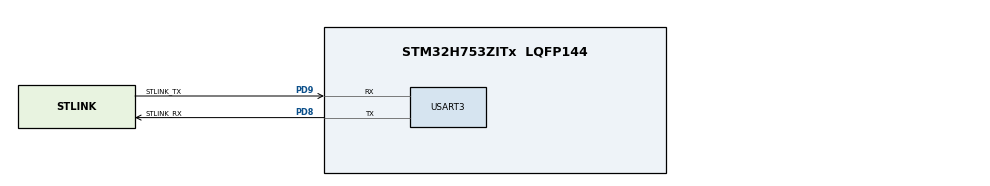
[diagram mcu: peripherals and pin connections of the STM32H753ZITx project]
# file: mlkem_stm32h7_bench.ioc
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CORTEX_M7.CPU_DCache=Disabled
CORTEX_M7.CPU_ICache=Disabled
CORTEX_M7.MPU_Control=MPU_PRIVILEGED_DEFAULT
CORTEX_M7.default_mode_Activation=1
Mcu.Family=STM32H7
Mcu.Name=STM32H753ZITx
Mcu.Package=LQFP144
NVIC.PriorityGroup=NVIC_PRIORITYGROUP_4
NVIC.TIM6_DAC_IRQn=true\:15\:0\:false\:false\:true\:false\:true\:true
NVIC.TimeBase=TIM6_DAC_IRQn
NVIC.TimeBaseIP=TIM6
PC14-OSC32_IN\ (OSC32_IN).Signal=RCC_OSC32_IN
PC15-OSC32_OUT\ (OSC32_OUT).Signal=RCC_OSC32_OUT
PD8.GPIO_Label=STLINK_RX
PD8.Mode=Asynchronous
PD8.Signal=USART3_TX
PD9.GPIO_Label=STLINK_TX
PD9.Mode=Asynchronous
PD9.Signal=USART3_RX
PH0-OSC_IN\ (PH0).Mode=HSE-External-Oscillator
PH0-OSC_IN\ (PH0).Signal=RCC_OSC_IN
PH1-OSC_OUT\ (PH1).Mode=HSE-External-Oscillator
PH1-OSC_OUT\ (PH1).Signal=RCC_OSC_OUT
ProjectManager.HeapSize=0x200
ProjectManager.StackSize=0x400
ProjectManager.TargetToolchain=STM32CubeIDE
RCC.ADCFreq_Value=16125000
RCC.APB1Freq_Value=60000000
RCC.APB2Freq_Value=60000000
RCC.APB3Freq_Value=60000000
RCC.APB4Freq_Value=60000000
RCC.CortexFreq_Value=480000000
RCC.D1PPRE=RCC_APB3_DIV2
RCC.D2PPRE1=RCC_APB1_DIV2
RCC.D2PPRE2=RCC_APB2_DIV2
RCC.D3PPRE=RCC_APB4_DIV2
RCC.DIVM1=4
RCC.DIVN1=480
RCC.DIVQ1=4
RCC.EnbaleCSS=true
RCC.HCLKFreq_Value=120000000
RCC.HPRE=RCC_HCLK_DIV4
RCC.HSE_VALUE=8000000
RCC.PLL2FRACN=0
RCC.PLL3FRACN=0
RCC.PLLFRACN=0
RCC.PLLSourceVirtual=RCC_PLLSOURCE_HSE
RCC.PWR_Regulator_Voltage_Scale=PWR_REGULATOR_VOLTAGE_SCALE2
RCC.SYSCLKFreq_VALUE=480000000
RCC.SYSCLKSource=RCC_SYSCLKSOURCE_PLLCLK
RCC.USBFreq_Value=240000000
TIM2.AutoReloadPreload=TIM_AUTORELOAD_PRELOAD_ENABLE
TIM2.Prescaler=119
USART3.VirtualMode-Asynchronous=VM_ASYNC
VP_MEMORYMAP_VS_MEMORYMAP.Mode=CurAppReg
VP_SYS_VS_tim6.Mode=TIM6
VP_TIM2_VS_ClockSourceINT.Mode=Internal
board=NUCLEO-H753ZI

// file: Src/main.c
/* USER CODE BEGIN Header */
/**
  ******************************************************************************
  * @file           : main.c
  * @brief          : Main program body
  ******************************************************************************
  * @attention
  *
  * Copyright (c) 2026 STMicroelectronics.
  * All rights reserved.
  *
  * This software is licensed under terms that can be found in the LICENSE file
  * in the root directory of this software component.
  * If no LICENSE file comes with this software, it is provided AS-IS.
  *
  ******************************************************************************
  */
/* USER CODE END Header */
#include "main.h"

/* USER CODE BEGIN Includes */
#include "benchmark.h"
/* USER CODE END Includes */

TIM_HandleTypeDef htim2;

UART_HandleTypeDef huart3;

void SystemClock_Config(void);
static void MPU_Config(void);
static void MX_GPIO_Init(void);
static void MX_TIM2_Init(void);
static void MX_USART3_UART_Init(void);

int main(void)
{

  /* MPU Configuration--------------------------------------------------------*/
  MPU_Config();

  /* MCU Configuration--------------------------------------------------------*/

  /* Reset of all peripherals, Initializes the Flash interface and the Systick. */
  HAL_Init();

  /* Configure the system clock */
  SystemClock_Config();

  /* Initialize all configured peripherals */
  MX_GPIO_Init();
  MX_TIM2_Init();
  MX_USART3_UART_Init();
  /* USER CODE BEGIN 2 */
  BenchmarkResult res;
  benchmark_run(&res);
  benchmark_print_results(&res);
  /* USER CODE END 2 */

  /* Infinite loop */
  while (1)
  {

  }
}

void SystemClock_Config(void)
{
  /* MCU boots on HSI 64 MHz by default in Renode.
   * Update CMSIS global for HAL tick calculations. */
  SystemCoreClock = 64000000UL;
}

static void MX_TIM2_Init(void)
{

  TIM_ClockConfigTypeDef sClockSourceConfig = {0};
  TIM_MasterConfigTypeDef sMasterConfig = {0};

  htim2.Instance = TIM2;
  htim2.Init.Prescaler = 63;  /* HSI 64MHz / 64 = 1MHz = 1us/tick (Renode: HSI used) */
  htim2.Init.CounterMode = TIM_COUNTERMODE_UP;
  htim2.Init.Period = 4294967295;
  htim2.Init.ClockDivision = TIM_CLOCKDIVISION_DIV1;
  htim2.Init.AutoReloadPreload = TIM_AUTORELOAD_PRELOAD_ENABLE;
  if (HAL_TIM_Base_Init(&htim2) != HAL_OK)
  {
    Error_Handler();
  }
  sClockSourceConfig.ClockSource = TIM_CLOCKSOURCE_INTERNAL;
  if (HAL_TIM_ConfigClockSource(&htim2, &sClockSourceConfig) != HAL_OK)
  {
    Error_Handler();
  }
  sMasterConfig.MasterOutputTrigger = TIM_TRGO_RESET;
  sMasterConfig.MasterSlaveMode = TIM_MASTERSLAVEMODE_DISABLE;
  if (HAL_TIMEx_MasterConfigSynchronization(&htim2, &sMasterConfig) != HAL_OK)
  {
    Error_Handler();
  }

}

static void MX_USART3_UART_Init(void)
{

  huart3.Instance = USART3;
  huart3.Init.BaudRate = 115200;
  huart3.Init.WordLength = UART_WORDLENGTH_8B;
  huart3.Init.StopBits = UART_STOPBITS_1;
  huart3.Init.Parity = UART_PARITY_NONE;
  huart3.Init.Mode = UART_MODE_TX_RX;
  huart3.Init.HwFlowCtl = UART_HWCONTROL_NONE;
  huart3.Init.OverSampling = UART_OVERSAMPLING_16;
  huart3.Init.OneBitSampling = UART_ONE_BIT_SAMPLE_DISABLE;
  huart3.Init.ClockPrescaler = UART_PRESCALER_DIV1;
  huart3.AdvancedInit.AdvFeatureInit = UART_ADVFEATURE_NO_INIT;
  if (HAL_UART_Init(&huart3) != HAL_OK)
  {
    Error_Handler();
  }
  /* Disable FIFO calls for Renode UART model compatibility */
  /* if (HAL_UARTEx_SetTxFifoThreshold(&huart3, UART_TXFIFO_THRESHOLD_1_8) != HAL_OK)
  {
    Error_Handler();
  }
  if (HAL_UARTEx_SetRxFifoThreshold(&huart3, UART_RXFIFO_THRESHOLD_1_8) != HAL_OK)
  {
    Error_Handler();
  }
  if (HAL_UARTEx_DisableFifoMode(&huart3) != HAL_OK)
  {
    Error_Handler();
  } */

}

static void MX_GPIO_Init(void)
{

  /* GPIO Ports Clock Enable */
  __HAL_RCC_GPIOC_CLK_ENABLE();
  __HAL_RCC_GPIOH_CLK_ENABLE();
  __HAL_RCC_GPIOD_CLK_ENABLE();

}

 /* MPU Configuration */

void MPU_Config(void)
{
  MPU_Region_InitTypeDef MPU_InitStruct = {0};

  /* Disables the MPU */
  HAL_MPU_Disable();

  /** Initializes and configures the Region and the memory to be protected
  */
  MPU_InitStruct.Enable = MPU_REGION_ENABLE;
  MPU_InitStruct.Number = MPU_REGION_NUMBER0;
  MPU_InitStruct.BaseAddress = 0x0;
  MPU_InitStruct.Size = MPU_REGION_SIZE_4GB;
  MPU_InitStruct.SubRegionDisable = 0x87;
  MPU_InitStruct.TypeExtField = MPU_TEX_LEVEL0;
  MPU_InitStruct.AccessPermission = MPU_REGION_NO_ACCESS;
  MPU_InitStruct.DisableExec = MPU_INSTRUCTION_ACCESS_DISABLE;
  MPU_InitStruct.IsShareable = MPU_ACCESS_SHAREABLE;
  MPU_InitStruct.IsCacheable = MPU_ACCESS_NOT_CACHEABLE;
  MPU_InitStruct.IsBufferable = MPU_ACCESS_NOT_BUFFERABLE;

  HAL_MPU_ConfigRegion(&MPU_InitStruct);
  /* Enables the MPU */
  HAL_MPU_Enable(MPU_PRIVILEGED_DEFAULT);

}

void HAL_TIM_PeriodElapsedCallback(TIM_HandleTypeDef *htim)
{
  if (htim->Instance == TIM6)
  {
    HAL_IncTick();
  }
}

void Error_Handler(void)
{
  __disable_irq();
  while (1)
  {
  }
}
